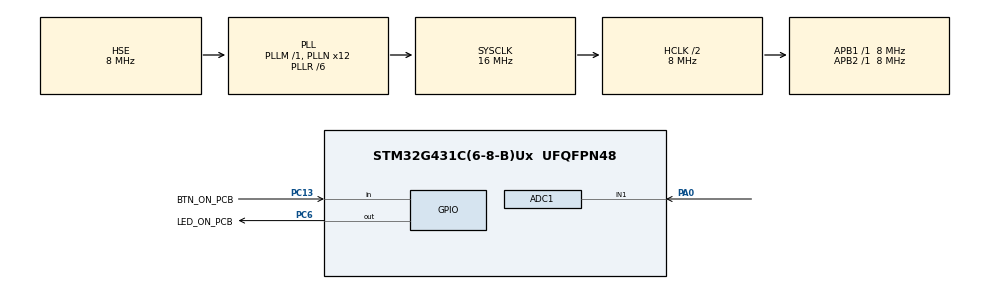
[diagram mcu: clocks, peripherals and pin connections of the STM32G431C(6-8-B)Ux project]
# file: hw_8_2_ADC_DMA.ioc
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ADC1.Channel-0\#ChannelRegularConversion=ADC_CHANNEL_1
ADC1.ContinuousConvMode=DISABLE
ADC1.DMAContinuousRequests=ENABLE
ADC1.ExternalTrigConv=ADC_EXTERNALTRIG_T15_TRGO
ADC1.NbrOfConversionFlag=1
ADC1.OffsetNumber-0\#ChannelRegularConversion=ADC_OFFSET_NONE
ADC1.Rank-0\#ChannelRegularConversion=1
ADC1.Resolution=ADC_RESOLUTION_12B
ADC1.SamplingTime-0\#ChannelRegularConversion=ADC_SAMPLETIME_12CYCLES_5
ADC1.master=1
Dma.ADC1.0.Direction=DMA_PERIPH_TO_MEMORY
Dma.ADC1.0.EventEnable=DISABLE
Dma.ADC1.0.Instance=DMA1_Channel1
Dma.ADC1.0.MemDataAlignment=DMA_MDATAALIGN_WORD
Dma.ADC1.0.MemInc=DMA_MINC_ENABLE
Dma.ADC1.0.Mode=DMA_CIRCULAR
Dma.ADC1.0.PeriphDataAlignment=DMA_PDATAALIGN_WORD
Dma.ADC1.0.PeriphInc=DMA_PINC_DISABLE
Dma.ADC1.0.Polarity=HAL_DMAMUX_REQ_GEN_RISING
Dma.ADC1.0.Priority=DMA_PRIORITY_LOW
Dma.ADC1.0.RequestNumber=1
Dma.ADC1.0.SignalID=NONE
Dma.ADC1.0.SyncEnable=DISABLE
Dma.ADC1.0.SyncPolarity=HAL_DMAMUX_SYNC_NO_EVENT
Dma.ADC1.0.SyncRequestNumber=1
Dma.ADC1.0.SyncSignalID=NONE
Dma.Request0=ADC1
Mcu.Family=STM32G4
Mcu.Name=STM32G431C(6-8-B)Ux
Mcu.Package=UFQFPN48
NVIC.DMA1_Channel1_IRQn=true\:0\:0\:false\:false\:true\:false\:true\:true
NVIC.PriorityGroup=NVIC_PRIORITYGROUP_4
PA0.Mode=IN1-Single-Ended
PA0.Signal=ADC1_IN1
PA13.Mode=Serial_Wire
PA13.Signal=SYS_JTMS-SWDIO
PA14.Mode=Serial_Wire
PA14.Signal=SYS_JTCK-SWCLK
PC13.GPIO_Label=BTN_ON_PCB
PC13.Signal=GPIO_Input
PC14-OSC32_IN.Mode=LSE-External-Oscillator
PC14-OSC32_IN.Signal=RCC_OSC32_IN
PC15-OSC32_OUT.Mode=LSE-External-Oscillator
PC15-OSC32_OUT.Signal=RCC_OSC32_OUT
PC6.GPIO_Label=LED_ON_PCB
PC6.Signal=GPIO_Output
PF0-OSC_IN.Mode=HSE-External-Oscillator
PF0-OSC_IN.Signal=RCC_OSC_IN
PF1-OSC_OUT.Mode=HSE-External-Oscillator
PF1-OSC_OUT.Signal=RCC_OSC_OUT
ProjectManager.HeapSize=0x200
ProjectManager.StackSize=0x400
ProjectManager.TargetToolchain=STM32CubeIDE
RCC.ADC12Freq_Value=16000000
RCC.AHBCLKDivider=RCC_SYSCLK_DIV2
RCC.AHBFreq_Value=8000000
RCC.APB1Freq_Value=8000000
RCC.APB1TimFreq_Value=8000000
RCC.APB2Freq_Value=8000000
RCC.APB2TimFreq_Value=8000000
RCC.CortexFreq_Value=8000000
RCC.EXTERNAL_CLOCK_VALUE=12288000
RCC.HCLKFreq_Value=8000000
RCC.HSE_VALUE=8000000
RCC.HSI48_VALUE=48000000
RCC.HSI_VALUE=16000000
RCC.PLLN=12
RCC.PLLR=RCC_PLLR_DIV6
RCC.PLLSourceVirtual=RCC_PLLSOURCE_HSE
RCC.SYSCLKFreq_VALUE=16000000
RCC.SYSCLKSource=RCC_SYSCLKSOURCE_PLLCLK
RCC.USBFreq_Value=48000000
RCC.VCOOutputFreq_Value=96000000
TIM15.Channel-Output\ Compare1\ No\ Output=TIM_CHANNEL_1
TIM15.OCMode_1=TIM_OCMODE_TOGGLE
TIM15.PeriodNoDither=10000-1
TIM15.Prescaler=80-1
TIM15.TIM_MasterOutputTrigger=TIM_TRGO_OC1REF
VP_SYS_VS_DBSignals.Mode=DisableDeadBatterySignals
VP_TIM15_VS_ClockSourceINT.Mode=Internal
VP_TIM15_VS_no_output1.Mode=Output Compare1 No Output
board=custom

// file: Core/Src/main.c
/* USER CODE BEGIN Header */
/**
  ******************************************************************************
  * @file           : main.c
  * @brief          : Main program body
  ******************************************************************************
  * @attention
  *
  * Copyright (c) 2025 STMicroelectronics.
  * All rights reserved.
  *
  * This software is licensed under terms that can be found in the LICENSE file
  * in the root directory of this software component.
  * If no LICENSE file comes with this software, it is provided AS-IS.
  *
  ******************************************************************************
  */
/* USER CODE END Header */
#include "main.h"

/* USER CODE BEGIN PD */
#define ADC_BUF_SZ  8
/* USER CODE END PD */

ADC_HandleTypeDef hadc1;
DMA_HandleTypeDef hdma_adc1;

TIM_HandleTypeDef htim15;

/* USER CODE BEGIN PV */
uint32_t adc1_ch1_val[ADC_BUF_SZ] = {0};

/* USER CODE END PV */

void SystemClock_Config(void);
static void MX_GPIO_Init(void);
static void MX_DMA_Init(void);
static void MX_ADC1_Init(void);
static void MX_TIM15_Init(void);

int main(void)
{

  /* MCU Configuration--------------------------------------------------------*/

  /* Reset of all peripherals, Initializes the Flash interface and the Systick. */
  HAL_Init();

  /* Configure the system clock */
  SystemClock_Config();

  /* Initialize all configured peripherals */
  MX_GPIO_Init();
  MX_DMA_Init();
  MX_ADC1_Init();
  MX_TIM15_Init();
  /* USER CODE BEGIN 2 */
  HAL_ADCEx_Calibration_Start(&hadc1, ADC_SINGLE_ENDED);
  HAL_TIM_Base_Start(&htim15);
  HAL_ADC_Start_DMA(&hadc1, adc1_ch1_val, ADC_BUF_SZ);
  /* USER CODE END 2 */

  /* Infinite loop */
  while (1)
  {

  }
}

void SystemClock_Config(void)
{
  RCC_OscInitTypeDef RCC_OscInitStruct = {0};
  RCC_ClkInitTypeDef RCC_ClkInitStruct = {0};

  /** Configure the main internal regulator output voltage
  */
  HAL_PWREx_ControlVoltageScaling(PWR_REGULATOR_VOLTAGE_SCALE1);

  /** Initializes the RCC Oscillators according to the specified parameters
  * in the RCC_OscInitTypeDef structure.
  */
  RCC_OscInitStruct.OscillatorType = RCC_OSCILLATORTYPE_HSE;
  RCC_OscInitStruct.HSEState = RCC_HSE_ON;
  RCC_OscInitStruct.PLL.PLLState = RCC_PLL_ON;
  RCC_OscInitStruct.PLL.PLLSource = RCC_PLLSOURCE_HSE;
  RCC_OscInitStruct.PLL.PLLM = RCC_PLLM_DIV1;
  RCC_OscInitStruct.PLL.PLLN = 12;
  RCC_OscInitStruct.PLL.PLLP = RCC_PLLP_DIV2;
  RCC_OscInitStruct.PLL.PLLQ = RCC_PLLQ_DIV2;
  RCC_OscInitStruct.PLL.PLLR = RCC_PLLR_DIV6;
  if (HAL_RCC_OscConfig(&RCC_OscInitStruct) != HAL_OK)
  {
    Error_Handler();
  }

  /** Initializes the CPU, AHB and APB buses clocks
  */
  RCC_ClkInitStruct.ClockType = RCC_CLOCKTYPE_HCLK|RCC_CLOCKTYPE_SYSCLK
                              |RCC_CLOCKTYPE_PCLK1|RCC_CLOCKTYPE_PCLK2;
  RCC_ClkInitStruct.SYSCLKSource = RCC_SYSCLKSOURCE_PLLCLK;
  RCC_ClkInitStruct.AHBCLKDivider = RCC_SYSCLK_DIV2;
  RCC_ClkInitStruct.APB1CLKDivider = RCC_HCLK_DIV1;
  RCC_ClkInitStruct.APB2CLKDivider = RCC_HCLK_DIV1;

  if (HAL_RCC_ClockConfig(&RCC_ClkInitStruct, FLASH_LATENCY_0) != HAL_OK)
  {
    Error_Handler();
  }
}

static void MX_ADC1_Init(void)
{

  ADC_MultiModeTypeDef multimode = {0};
  ADC_ChannelConfTypeDef sConfig = {0};

  /** Common config
  */
  hadc1.Instance = ADC1;
  hadc1.Init.ClockPrescaler = ADC_CLOCK_SYNC_PCLK_DIV2;
  hadc1.Init.Resolution = ADC_RESOLUTION_12B;
  hadc1.Init.DataAlign = ADC_DATAALIGN_RIGHT;
  hadc1.Init.GainCompensation = 0;
  hadc1.Init.ScanConvMode = ADC_SCAN_DISABLE;
  hadc1.Init.EOCSelection = ADC_EOC_SINGLE_CONV;
  hadc1.Init.LowPowerAutoWait = DISABLE;
  hadc1.Init.ContinuousConvMode = DISABLE;
  hadc1.Init.NbrOfConversion = 1;
  hadc1.Init.DiscontinuousConvMode = DISABLE;
  hadc1.Init.ExternalTrigConv = ADC_EXTERNALTRIG_T15_TRGO;
  hadc1.Init.ExternalTrigConvEdge = ADC_EXTERNALTRIGCONVEDGE_RISING;
  hadc1.Init.DMAContinuousRequests = ENABLE;
  hadc1.Init.Overrun = ADC_OVR_DATA_PRESERVED;
  hadc1.Init.OversamplingMode = DISABLE;
  if (HAL_ADC_Init(&hadc1) != HAL_OK)
  {
    Error_Handler();
  }

  /** Configure the ADC multi-mode
  */
  multimode.Mode = ADC_MODE_INDEPENDENT;
  if (HAL_ADCEx_MultiModeConfigChannel(&hadc1, &multimode) != HAL_OK)
  {
    Error_Handler();
  }

  /** Configure Regular Channel
  */
  sConfig.Channel = ADC_CHANNEL_1;
  sConfig.Rank = ADC_REGULAR_RANK_1;
  sConfig.SamplingTime = ADC_SAMPLETIME_12CYCLES_5;
  sConfig.SingleDiff = ADC_SINGLE_ENDED;
  sConfig.OffsetNumber = ADC_OFFSET_NONE;
  sConfig.Offset = 0;
  if (HAL_ADC_ConfigChannel(&hadc1, &sConfig) != HAL_OK)
  {
    Error_Handler();
  }

}

static void MX_TIM15_Init(void)
{

  TIM_ClockConfigTypeDef sClockSourceConfig = {0};
  TIM_MasterConfigTypeDef sMasterConfig = {0};
  TIM_OC_InitTypeDef sConfigOC = {0};
  TIM_BreakDeadTimeConfigTypeDef sBreakDeadTimeConfig = {0};

  htim15.Instance = TIM15;
  htim15.Init.Prescaler = 80-1;
  htim15.Init.CounterMode = TIM_COUNTERMODE_UP;
  htim15.Init.Period = 9999;
  htim15.Init.ClockDivision = TIM_CLOCKDIVISION_DIV1;
  htim15.Init.RepetitionCounter = 0;
  htim15.Init.AutoReloadPreload = TIM_AUTORELOAD_PRELOAD_DISABLE;
  if (HAL_TIM_Base_Init(&htim15) != HAL_OK)
  {
    Error_Handler();
  }
  sClockSourceConfig.ClockSource = TIM_CLOCKSOURCE_INTERNAL;
  if (HAL_TIM_ConfigClockSource(&htim15, &sClockSourceConfig) != HAL_OK)
  {
    Error_Handler();
  }
  if (HAL_TIM_OC_Init(&htim15) != HAL_OK)
  {
    Error_Handler();
  }
  sMasterConfig.MasterOutputTrigger = TIM_TRGO_OC1REF;
  sMasterConfig.MasterSlaveMode = TIM_MASTERSLAVEMODE_DISABLE;
  if (HAL_TIMEx_MasterConfigSynchronization(&htim15, &sMasterConfig) != HAL_OK)
  {
    Error_Handler();
  }
  sConfigOC.OCMode = TIM_OCMODE_TOGGLE;
  sConfigOC.Pulse = 0;
  sConfigOC.OCPolarity = TIM_OCPOLARITY_HIGH;
  sConfigOC.OCNPolarity = TIM_OCNPOLARITY_HIGH;
  sConfigOC.OCFastMode = TIM_OCFAST_DISABLE;
  sConfigOC.OCIdleState = TIM_OCIDLESTATE_RESET;
  sConfigOC.OCNIdleState = TIM_OCNIDLESTATE_RESET;
  if (HAL_TIM_OC_ConfigChannel(&htim15, &sConfigOC, TIM_CHANNEL_1) != HAL_OK)
  {
    Error_Handler();
  }
  sBreakDeadTimeConfig.OffStateRunMode = TIM_OSSR_DISABLE;
  sBreakDeadTimeConfig.OffStateIDLEMode = TIM_OSSI_DISABLE;
  sBreakDeadTimeConfig.LockLevel = TIM_LOCKLEVEL_OFF;
  sBreakDeadTimeConfig.DeadTime = 0;
  sBreakDeadTimeConfig.BreakState = TIM_BREAK_DISABLE;
  sBreakDeadTimeConfig.BreakPolarity = TIM_BREAKPOLARITY_HIGH;
  sBreakDeadTimeConfig.BreakFilter = 0;
  sBreakDeadTimeConfig.AutomaticOutput = TIM_AUTOMATICOUTPUT_DISABLE;
  if (HAL_TIMEx_ConfigBreakDeadTime(&htim15, &sBreakDeadTimeConfig) != HAL_OK)
  {
    Error_Handler();
  }

}

static void MX_DMA_Init(void)
{

  /* DMA controller clock enable */
  __HAL_RCC_DMAMUX1_CLK_ENABLE();
  __HAL_RCC_DMA1_CLK_ENABLE();

  /* DMA interrupt init */
  /* DMA1_Channel1_IRQn interrupt configuration */
  HAL_NVIC_SetPriority(DMA1_Channel1_IRQn, 0, 0);
  HAL_NVIC_EnableIRQ(DMA1_Channel1_IRQn);

}

static void MX_GPIO_Init(void)
{
  GPIO_InitTypeDef GPIO_InitStruct = {0};

  /* GPIO Ports Clock Enable */
  __HAL_RCC_GPIOC_CLK_ENABLE();
  __HAL_RCC_GPIOF_CLK_ENABLE();
  __HAL_RCC_GPIOA_CLK_ENABLE();

  /*Configure GPIO pin Output Level */
  HAL_GPIO_WritePin(LED_ON_PCB_GPIO_Port, LED_ON_PCB_Pin, GPIO_PIN_RESET);

  /*Configure GPIO pin : BTN_ON_PCB_Pin */
  GPIO_InitStruct.Pin = BTN_ON_PCB_Pin;
  GPIO_InitStruct.Mode = GPIO_MODE_INPUT;
  GPIO_InitStruct.Pull = GPIO_NOPULL;
  HAL_GPIO_Init(BTN_ON_PCB_GPIO_Port, &GPIO_InitStruct);

  /*Configure GPIO pin : LED_ON_PCB_Pin */
  GPIO_InitStruct.Pin = LED_ON_PCB_Pin;
  GPIO_InitStruct.Mode = GPIO_MODE_OUTPUT_PP;
  GPIO_InitStruct.Pull = GPIO_NOPULL;
  GPIO_InitStruct.Speed = GPIO_SPEED_FREQ_LOW;
  HAL_GPIO_Init(LED_ON_PCB_GPIO_Port, &GPIO_InitStruct);

}

/* USER CODE BEGIN 4 */
void HAL_ADC_ConvHalfCpltCallback(ADC_HandleTypeDef *hadc)
{
  HAL_GPIO_WritePin(LED_ON_PCB_GPIO_Port, LED_ON_PCB_Pin, GPIO_PIN_SET);
}

void HAL_ADC_ConvCpltCallback(ADC_HandleTypeDef *hadc)
{
  HAL_GPIO_WritePin(LED_ON_PCB_GPIO_Port, LED_ON_PCB_Pin, GPIO_PIN_RESET);
}
/* USER CODE END 4 */

void Error_Handler(void)
{
  __disable_irq();
  while (1)
  {
  }
}
